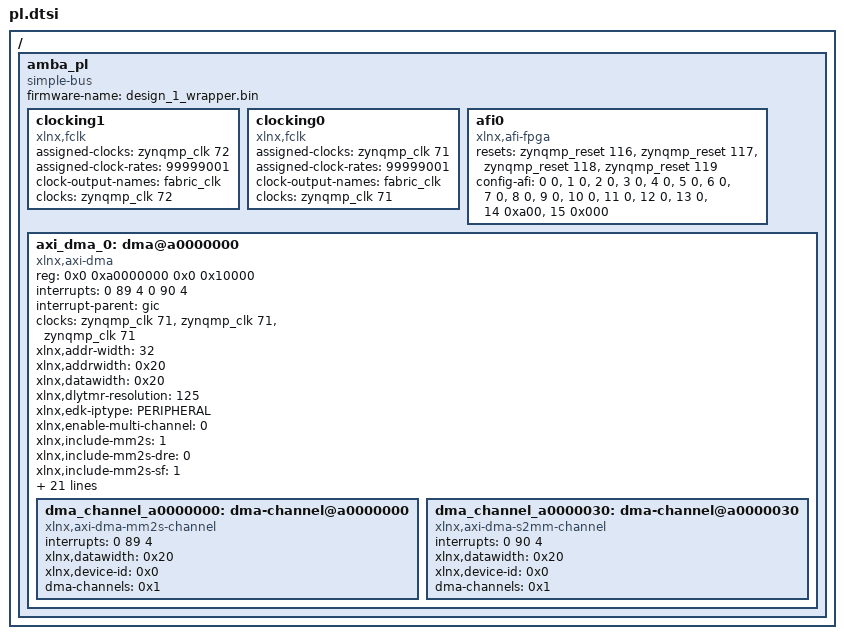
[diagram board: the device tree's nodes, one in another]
/dts-v1/;
/plugin/;

/ {
    fragment@0 {
        target-path = "/";
        __overlay__ {
            amba_pl: amba_pl {
                compatible = "simple-bus";
                #address-cells = <2>;
                #size-cells = <2>;
                ranges;
                firmware-name = "design_1_wrapper.bin";

                clocking1: clocking1 {
                    compatible = "xlnx,fclk";
                    status = "okay";
                    assigned-clocks = <&zynqmp_clk 72>;
                    assigned-clock-rates = <99999001>;
                    #clock-cells = <0>;
                    clock-output-names = "fabric_clk";
                    clocks = <&zynqmp_clk 72>;
                };

                clocking0: clocking0 {
                    compatible = "xlnx,fclk";
                    status = "okay";
                    assigned-clocks = <&zynqmp_clk 71>;
                    assigned-clock-rates = <99999001>;
                    #clock-cells = <0>;
                    clock-output-names = "fabric_clk";
                    clocks = <&zynqmp_clk 71>;
                };

                afi0: afi0 {
                    compatible = "xlnx,afi-fpga";
                    status = "okay";
                    resets = <&zynqmp_reset 116>, <&zynqmp_reset 117>,
                             <&zynqmp_reset 118>, <&zynqmp_reset 119>;
                    config-afi = <0 0>, <1 0>, <2 0>, <3 0>,
                                 <4 0>, <5 0>, <6 0>, <7 0>,
                                 <8 0>, <9 0>, <10 0>, <11 0>,
                                 <12 0>, <13 0>, <14 0xa00>, <15 0x000>;
                };

                axi_dma_0: dma@a0000000 {
                    compatible = "xlnx,axi-dma";
                    status = "okay";
                    reg = <0x0 0xa0000000 0x0 0x10000>;
                    interrupts = <0 89 4 0 90 4>;
                    interrupt-parent = <&gic>;
                    interrupt-names = "mm2s_introut", "s2mm_introut";
                    #dma-cells = <1>;
                    clocks = <&zynqmp_clk 71>, <&zynqmp_clk 71>, <&zynqmp_clk 71>;
                    clock-names = "m_axi_mm2s_aclk", "m_axi_s2mm_aclk", "s_axi_lite_aclk";

                    xlnx,addr-width = <32>;
                    xlnx,addrwidth = <0x20>;
                    xlnx,datawidth = <0x20>;
                    xlnx,dlytmr-resolution = <125>;
                    xlnx,edk-iptype = "PERIPHERAL";
                    xlnx,enable-multi-channel = <0>;
                    xlnx,include-mm2s = <1>;
                    xlnx,include-mm2s-dre = <0>;
                    xlnx,include-mm2s-sf = <1>;
                    xlnx,include-s2mm = <1>;
                    xlnx,include-s2mm-dre = <0>;
                    xlnx,include-s2mm-sf = <1>;
                    xlnx,increase-throughput = <0>;
                    xlnx,ip-name = "axi_dma";
                    xlnx,m-axi-mm2s-data-width = <32>;
                    xlnx,m-axi-s2mm-data-width = <32>;
                    xlnx,m-axis-mm2s-tdata-width = <32>;
                    xlnx,mm2s-burst-size = <16>;
                    xlnx,mm2s-data-width = <0x20>;
                    xlnx,micro-dma = <0>;
                    xlnx,name = "axi_dma_0";
                    xlnx,num-mm2s-channels = <1>;
                    xlnx,num-s2mm-channels = <1>;
                    xlnx,prmry-is-aclk-async = <0>;
                    xlnx,rable = <0>;
                    xlnx,s-axis-s2mm-tdata-width = <32>;
                    xlnx,sg-include-stscntrl-strm = <0>;
                    xlnx,sg-length-width = <14>;
                    xlnx,sg-use-stsapp-length = <0>;
                    xlnx,single-interface = <0>;

                    dma_channel_a0000000: dma-channel@a0000000 {
                        compatible = "xlnx,axi-dma-mm2s-channel";
                        interrupts = <0 89 4>;
                        xlnx,datawidth = <0x20>;
                        xlnx,device-id = <0x0>;
                        dma-channels = <0x1>;
                    };

                    dma_channel_a0000030: dma-channel@a0000030 {
                        compatible = "xlnx,axi-dma-s2mm-channel";
                        interrupts = <0 90 4>;
                        xlnx,datawidth = <0x20>;
                        xlnx,device-id = <0x0>;
                        dma-channels = <0x1>;
                    };
                };
            };
        };
    };
};
